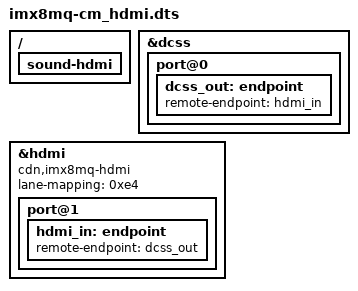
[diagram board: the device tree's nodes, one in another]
// SPDX-License-Identifier: (GPL-2.0 OR MIT)
/*
 * Copyright 2017 NXP
 * Copyright (C) 2020-2021 Ronetix, Ilko Iliev <iliev@ronetix.at>
 */

#include "imx8mq-cm.dtsi"

/ {
	sound-hdmi {
		status = "okay";
	};
};

&dcss {
	status = "okay";

	port@0 {
		dcss_out: endpoint {
			  remote-endpoint = <&hdmi_in>;
		};
	};
};

&hdmi {
	compatible = "cdn,imx8mq-hdmi";
	lane-mapping = <0xe4>;
	status = "okay";
	port@1 {
		hdmi_in: endpoint {
			remote-endpoint = <&dcss_out>;
		};
	};
};

